VERSION "HIPBNYYYYYYYYYYYYYYYYYYYYYYYYYYYYYYYYYYYYY/4/%%%/4/'%**4YYY///"

NS_ :

BS_:

BU_: ME_AWS_CANA
VAL_TABLE_ Vt_Float_Parameter_Unit 5 "MInute" 4 "Second" 3 "Feet" 2 "Meter" 1 "MPH" 0 "KMH" ;
VAL_TABLE_ Vt_Duration_Unit 3 "hour" 2 "minute" 1 "10_seconds" 0 "second" ;
VAL_TABLE_ Vt_ON_OFF 1 "on" 0 "off" ;

BO_ 3221225472 VECTOR__INDEPENDENT_SIG_MSG: 0 Vector__XXX
 SG_ reserved_1 : 0|8@1- (1,0) [0|0] "" Vector__XXX

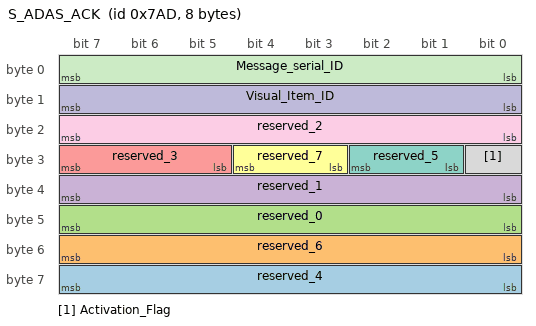
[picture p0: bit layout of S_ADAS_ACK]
BO_ 1965 S_ADAS_ACK: 8 ME_AWS_CANA
 SG_ reserved_4 : 56|8@1+ (1,0) [0|255] "" Vector__XXX
 SG_ reserved_6 : 48|8@1+ (1,0) [0|255] "" Vector__XXX
 SG_ reserved_0 : 40|8@1+ (1,0) [0|255] "" Vector__XXX
 SG_ reserved_1 : 32|8@1+ (1,0) [0|255] "" Vector__XXX
 SG_ reserved_3 : 29|3@1+ (1,0) [0|7] "enum" Vector__XXX
 SG_ reserved_7 : 27|2@1+ (1,0) [0|3] "enum" Vector__XXX
 SG_ reserved_5 : 25|2@1+ (1,0) [0|3] "enum" Vector__XXX
 SG_ Activation_Flag : 24|1@1- (1,0) [0|1] "bool" Vector__XXX
 SG_ reserved_2 : 16|8@1- (1,0) [0|0] "" Vector__XXX
 SG_ Visual_Item_ID : 8|8@1+ (1,0) [1|255] "" Vector__XXX
 SG_ Message_serial_ID : 0|8@1+ (1,0) [1|255] "" Vector__XXX

CM_ BO_ 3221225472 "This is a message for not used signals, created by Vector CANdb++ DBC OLE DB Provider.";
VAL_ 1965 reserved_3 5 "MInute" 4 "Second" 3 "Feet" 2 "Meter" 1 "MPH" 0 "KMH" ;
VAL_ 1965 reserved_7 3 "hour" 2 "minute" 1 "10_seconds" 0 "second" ;
VAL_ 1965 reserved_5 3 "hour" 2 "minute" 1 "10_seconds" 0 "second" ;
